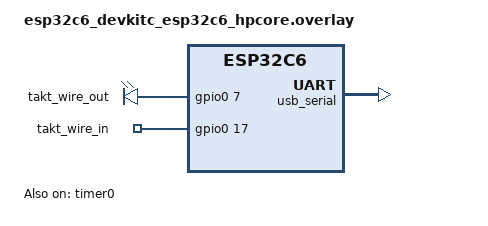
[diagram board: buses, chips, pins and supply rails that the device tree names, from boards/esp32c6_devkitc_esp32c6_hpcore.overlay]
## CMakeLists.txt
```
# Takt unter Zephyr mit Treibern aus dem Devicetree (8.10, 12.11; M11
# Schritt 19): die Messschleife `takt/wire.takt` auf der Drahtbruecke des
# Boards, auf `blackpill_f401cc` (PA0 an PA1) und
# `esp32c6_devkitc/esp32c6/hpcore` (GPIO7 an GPIO17).
#
#   west build -b blackpill_f401cc examples/zephyr-gpio --
#       -DTAKT_EXECUTABLE=<takt> -DTAKT_SDK_LIBRARY=<SDK-Archiv des Ziels>
#
# `takt/wire.hw` nennt fuer beide Kanaele den Treiber `zephyr-gpio` und als
# `port` die Labels der Knoten aus boards/*.overlay; das Modul gibt `takt
# build` dafuer `--zephyr` und uebersetzt `wire_zephyr.c` mit. Leitung und
# Rueckgabe des Boards teilt das Beispiel mit `examples/zephyr`.

cmake_minimum_required(VERSION 3.20.0)

set(TAKT_ROOT ${CMAKE_CURRENT_LIST_DIR}/../..)
list(APPEND ZEPHYR_EXTRA_MODULES ${TAKT_ROOT})
find_package(Zephyr REQUIRED HINTS $ENV{ZEPHYR_BASE})
project(takt_zephyr_gpio C)

takt_add_program(wire SOURCE takt/wire.takt HARDWARE takt/wire.hw)

set(shared ${TAKT_ROOT}/examples/zephyr/src)
target_include_directories(app PRIVATE ${shared})
target_sources(app PRIVATE src/main.c ${shared}/line.c ${shared}/handback.c)
if(BOARD STREQUAL "blackpill_f401cc")
  target_sources(app PRIVATE ${shared}/handback_stm32f401.c)
else()
  target_sources(app PRIVATE ${shared}/handback_reboot.c)
endif()
target_link_libraries(app PRIVATE wire)
```

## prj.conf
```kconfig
# Takt unter Zephyr mit Treibern aus dem Devicetree (8.10, 12.11): das Modul,
# die Pins und die Leitung.
CONFIG_TAKT=y
CONFIG_GPIO=y

# Die Leitung (12.2, 12.5): das UART-Geraet `takt,line` des Devicetree,
# gesendet aus seinem Interrupt, damit der Schritt nie auf sie wartet.
CONFIG_SERIAL=y
CONFIG_UART_INTERRUPT_DRIVEN=y
CONFIG_RING_BUFFER=y

# Die Frist ist auf einen Systemtick genau: 10 us statt der Vorgabe 100 us.
CONFIG_SYS_CLOCK_TICKS_PER_SEC=100000

# `main` wartet unter dem Jobfaden, bis der Lauf endet, und schreibt die
# Bilanz (`takt_core_report`).
CONFIG_MAIN_THREAD_PRIORITY=14
CONFIG_MAIN_STACK_SIZE=4096
```

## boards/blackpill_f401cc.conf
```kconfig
# Board 1 (plan/f401.md): Sektor 0 haelt der HID-Bootloader, Sektor 1 das
# Sprungbrett; die Anwendung beginnt in Sektor 4 (0x0801_0000), wo das
# Sprungbrett sie startet, wie in examples/zephyr.
CONFIG_FLASH_LOAD_OFFSET=0x10000
CONFIG_FLASH_LOAD_SIZE=0x30000

# Die FPU mit der ABI des Tripels `thumbv7em-none-eabihf`; `CONFIG_TAKT`
# waehlt dazu `CONFIG_FPU_SHARING`.
CONFIG_FPU=y
CONFIG_FP_HARDABI=y

# USART1 ist die Leitung, keine Konsole daneben.
CONFIG_CONSOLE=n
CONFIG_UART_CONSOLE=n
```

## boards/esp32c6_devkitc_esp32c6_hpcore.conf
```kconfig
# Board 2: GPIO17 gehoert der Drahtbruecke, nicht UART0; ohne UART0 keine
# Konsole. `TAKT` auf der Leitung startet das Board neu.
CONFIG_CONSOLE=n
CONFIG_UART_CONSOLE=n
CONFIG_REBOOT=y
# Die Uhr des Ports ist der Zaehler aus dem Overlay (`takt,timer`).
CONFIG_COUNTER=y
```

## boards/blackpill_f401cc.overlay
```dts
/* Board 1: die Leitung auf USART1 wie in examples/zephyr und die
 * Drahtbruecke PA0 an PA1 (plan/f401.md) als zwei Knoten mit `gpios`, deren
 * Labels `takt/wire.hw` nennt. `gpio-leds` und `gpio-keys` tragen nur die
 * Pins: Ohne CONFIG_LED und CONFIG_INPUT greift kein Treiber des
 * Zephyr-Kerns nach ihnen. */
/ {
	chosen {
		takt,line = &usart1;
	};

	takt-wire-out {
		compatible = "gpio-leds";

		takt_wire_out: wire-out {
			gpios = <&gpioa 0 GPIO_ACTIVE_HIGH>;
		};
	};

	takt-wire-in {
		compatible = "gpio-keys";

		takt_wire_in: wire-in {
			gpios = <&gpioa 1 GPIO_ACTIVE_HIGH>;
		};
	};
};

&usart1 {
	current-speed = <921600>;
};
```

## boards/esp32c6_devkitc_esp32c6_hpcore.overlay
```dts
/* Board 2 (plan/esp32c6.md): ein ESP32-C6-DevKitM-1-N4 mit 4 MB Flash wie in
 * examples/zephyr, die Leitung auf dem USB-Serial-JTAG und die
 * Drahtbruecke GPIO7 an GPIO17 als zwei Knoten mit `gpios`, deren Labels
 * `takt/wire.hw` nennt. GPIO17 ist sonst der Empfaenger von UART0; der
 * bleibt aus. `gpio-leds` und `gpio-keys` tragen nur die Pins: Ohne
 * CONFIG_LED und CONFIG_INPUT greift kein Treiber des Zephyr-Kerns nach
 * ihnen. */
/ {
	chosen {
		takt,line = &usb_serial;
		takt,timer = &takt_timer;
	};

	takt-wire-out {
		compatible = "gpio-leds";

		takt_wire_out: wire-out {
			gpios = <&gpio0 7 GPIO_ACTIVE_HIGH>;
		};
	};

	takt-wire-in {
		compatible = "gpio-keys";

		takt_wire_in: wire-in {
			gpios = <&gpio0 17 GPIO_ACTIVE_HIGH>;
		};
	};
};

/* Die Uhr des Ports (FB-733, FB-781): Timer 0 der Gruppe 0 mit 1 MHz wie in
 * examples/zephyr; Takt stellt seine Frist auf ihn, auf 1 us genau und
 * unabhaengig vom Systemzeitgeber. */
&timer0 {
	prescaler = <80>;
	status = "okay";

	takt_timer: counter {
		status = "okay";
	};
};

&flash0 {
	reg = <0x0 DT_SIZE_M(4)>;
};

&uart0 {
	status = "disabled";
};

&usb_serial {
	status = "okay";
};
```

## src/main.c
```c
/* Takt unter Zephyr mit Treibern aus dem Devicetree (8.10, 12.11; M11
 * Schritt 19): die Messschleife `takt/wire.takt` auf der Drahtbruecke des
 * Boards.
 *
 * `takt_add_program` liefert `wire` (Bibliothek, `wire.h`, `takt_sdk.h`) und
 * unter Zephyr die Treiber beider Pins (`wire_zephyr.c`, `wire_zephyr.h`);
 * das SDK-Archiv bringt den Kern, das Modul den Port. Diese Anwendung stellt
 * den Rest, den der Wirt stellt (12.11): die Leitung, den Watchdog und beide
 * Stacks. Der Trace zeichnet jeden Pegel auf, den der Eingang las; der
 * Board-Test vergleicht ihn mit dem Interpreter und mit dem Pegel, den der
 * Ausgang im Tick davor schrieb.
 */
#include <stdint.h>

#include <zephyr/kernel.h>
#include <zephyr/sys/printk.h>

#include "handback.h"
#include "line.h"
#include "takt_rtos.h"
#include "takt_sdk.h"
#include "wire.h"
#include "wire_zephyr.h"

/* So viele Ticks faehrt der Port. */
#define TICKS 2000U

/* So lange schlaeft `main` zwischen zwei Blicken auf den Lauf. */
#define POLL_MS 10

/* Luft ueber der Schranke des Programms in jedem Stack, damit eine tiefere
 * Messung in der Bilanz steht, statt dass der Stackwaechter sie als Fault
 * meldet (12.3). */
#define STACK_SLACK 1024U

/* Der Watchdog des Wirts (12.11): Dieses Beispiel startet keinen. */
static void kick(void *ctx) {
    ARG_UNUSED(ctx);
}

/* Die Uhr des Ports als Kopfzeile: Quelle und Rate (FB-733); auf dem C6
 * der Zaehler aus dem Overlay, auf dem F401 der Systemtick. */
static void clock_line(void) {
    char line[48];
    uint32_t hz = 0U;
    const char *source = takt_os_clock(&hz);
    (void)snprintk(line, sizeof line, "takt uhr %s %u Hz\n", source, (unsigned int)hz);
    takt_board_trace(line);
}

/* Faehrt den Kern `core` ueber den Port und schreibt die Bilanz. Verlangt
 * der Host das Board zurueck, gibt `main` es sofort ab. */
static void drive(takt_core *core) {
    /* Kernel-Stacks fuer Supervisor-Faeden (`ports/zephyr/takt_os_types.h`). */
    static K_KERNEL_STACK_DEFINE(tick_stack, WIRE_TICK_STACK_BYTES + STACK_SLACK);
    static K_KERNEL_STACK_DEFINE(job_stack, WIRE_JOB_STACK_BYTES + STACK_SLACK);
    static struct takt_rtos rtos;
    const struct takt_rtos_config config = {
        .ticks = TICKS,
        .tick_ns = WIRE_TICK_NS,
        .tick_stack = tick_stack,
        .tick_stack_bytes = sizeof tick_stack,
        .job_stack = job_stack,
        .job_stack_bytes = sizeof job_stack,
        .step_priority = TAKT_OS_STEP_PRIORITY,
        .job_priority = TAKT_OS_JOB_PRIORITY,
    };
    struct takt_stacks stacks;
    const struct takt_stacks *measured = NULL;
    if (takt_rtos_start(&rtos, core, &config) == 0) {
        while (takt_rtos_running(&rtos) != 0) {
            handback_serve();
            (void)k_msleep(POLL_MS);
        }
        if (takt_rtos_join(&rtos, &stacks) == 0) {
            stacks.tick_bound = WIRE_TICK_STACK_BYTES;
            stacks.job_bound = WIRE_JOB_STACK_BYTES;
            measured = &stacks;
        }
    } else {
        takt_board_trace("takt port: kein Start\n");
    }
    takt_core_report(core, measured, NULL);
}

/* Ein Schritt vor dem Lauf scheiterte: Er steht mit seinem Code auf der
 * Leitung, bevor das Board auf den Host wartet. Ohne `takt_line_flush`
 * bliebe er im Ring, denn den gibt der Kern erst nach einem Tick ab, und
 * die Leitung schwiege (FB-757). */
static void refused(const char *what, int32_t code) {
    takt_board_trace(what);
    takt_board_trace_i64(code);
    takt_board_trace("\n");
    takt_line_flush();
}

int main(void) {
    static uint8_t ring[4096];
    static struct wire_arena arena;
    static takt_core core;
    static const struct takt_watchdog watchdog = {NULL, kick};
    struct takt_line line;
    const char *channel = NULL;
    if ((line_open(&line) == 0) && (takt_line_init(&line, ring, sizeof ring) == TAKT_OK)) {
        takt_board_trace("takt auf zephyr mit pins aus dem devicetree\n" TAKT_RTOS_PROTECTION "\n");
        clock_line();
        takt_line_flush();
        if (wire_zephyr_init(&channel) != 0) {
            /* Die Pins vor dem Kern (8.10): Ein Kanal ohne Pin beginnt nicht. */
            takt_board_trace("takt pins: nicht eingerichtet: ");
            takt_board_trace(channel);
            takt_board_trace("\n");
            takt_line_flush();
        } else {
            takt_line_mark();
            takt_line_flush();
            const int32_t status = takt_core_init(&core, &wire_ops, &arena, NULL, TAKT_PROFILE_SHARED, &watchdog);
            if (status != TAKT_OK) {
                refused("takt kern: nicht bereit ", status);
            } else {
                drive(&core);
            }
        }
    }
    handback_await();
    return 0;
}
```
